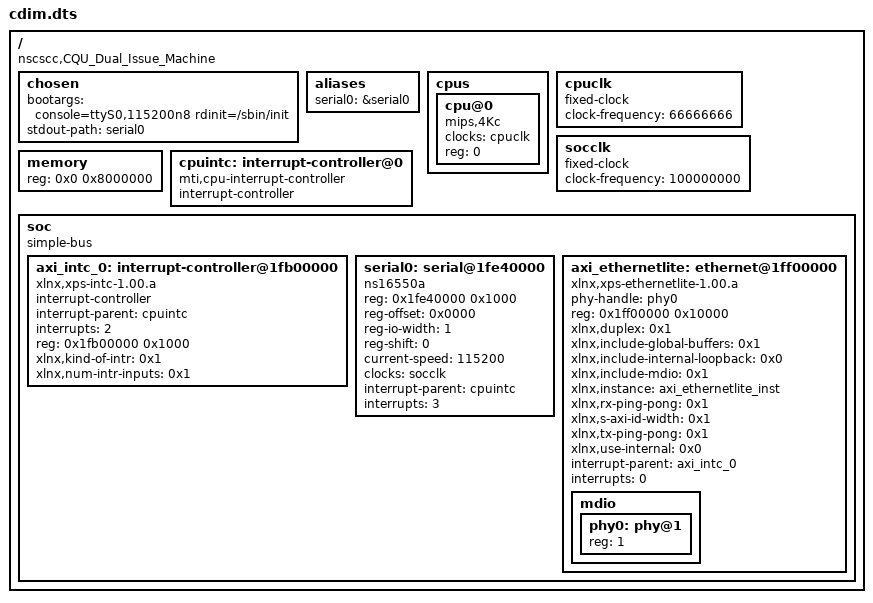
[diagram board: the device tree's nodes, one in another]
/dts-v1/;

#include <dt-bindings/interrupt-controller/irq.h>

/ {
	compatible = "nscscc,CQU_Dual_Issue_Machine";
	#address-cells = <1>;
	#size-cells = <1>;

	chosen {
		bootargs = "console=ttyS0,115200n8 rdinit=/sbin/init";
		stdout-path = "serial0";
	};

	aliases {
		serial0 = &serial0;
	};

	cpus {
		#address-cells = <1>;
		#size-cells = <0>;
		cpu@0 {
			device_type = "cpu";
			compatible = "mips,4Kc";
			clocks = <&cpuclk>;
			reg = <0>;
		};
	};

	cpuclk: cpuclk {
		compatible = "fixed-clock";
		clock-frequency = <66666666>;
		#clock-cells = <0>;
	};

	socclk: socclk {
		compatible = "fixed-clock";
		clock-frequency = <100000000>;
		#clock-cells = <0>;
	};

	memory {
		device_type = "memory";
		reg = <0x0 0x8000000>;
	};

	cpuintc: interrupt-controller@0 {
		#address-cells = <0>;
		#interrupt-cells = <1>;
		interrupt-controller;
		compatible = "mti,cpu-interrupt-controller";
	};

	soc {
		compatible = "simple-bus";
		#address-cells = <1>;
		#size-cells = <1>;
		#interrupt-cells = <1>;
		ranges;

		axi_intc_0: interrupt-controller@1fb00000 {
			#interrupt-cells = <1>;
			compatible = "xlnx,xps-intc-1.00.a";
			interrupt-controller;
			interrupt-parent = <&cpuintc>;
			interrupts = <2>;
			reg = <0x1fb00000 0x1000>;
			xlnx,kind-of-intr = <0x1>;
			xlnx,num-intr-inputs = <0x1>;
			status = "okay";
		};

		serial0: serial@1fe40000 {
			device_type = "serial";
			compatible = "ns16550a";
			reg = <0x1fe40000 0x1000>;
			reg-offset = <0x0000>;
			reg-io-width = <1>;
			reg-shift = <0>;
			current-speed = <115200>;
			clocks = <&socclk>;
			interrupt-parent = <&cpuintc>;
			interrupts = <3>;
		};

		axi_ethernetlite: ethernet@1ff00000 {
			compatible = "xlnx,xps-ethernetlite-1.00.a";
			device_type = "network";
			phy-handle = <&phy0>;
			reg = <0x1ff00000 0x10000>;
			xlnx,duplex = <0x1>;
			xlnx,include-global-buffers = <0x1>;
			xlnx,include-internal-loopback = <0x0>;
			xlnx,include-mdio = <0x1>;
			xlnx,instance = "axi_ethernetlite_inst";
			xlnx,rx-ping-pong = <0x1>;
			xlnx,s-axi-id-width = <0x1>;
			xlnx,tx-ping-pong = <0x1>;
			xlnx,use-internal = <0x0>;
			interrupt-parent = <&axi_intc_0>;
			interrupts = <0>;
			status = "okay";
			mdio {
				#address-cells = <1>;
				#size-cells = <0>;
				phy0: phy@1 {
					device_type = "ethernet-phy";
					reg = <1>;
				};
			};
		};

	};
};

